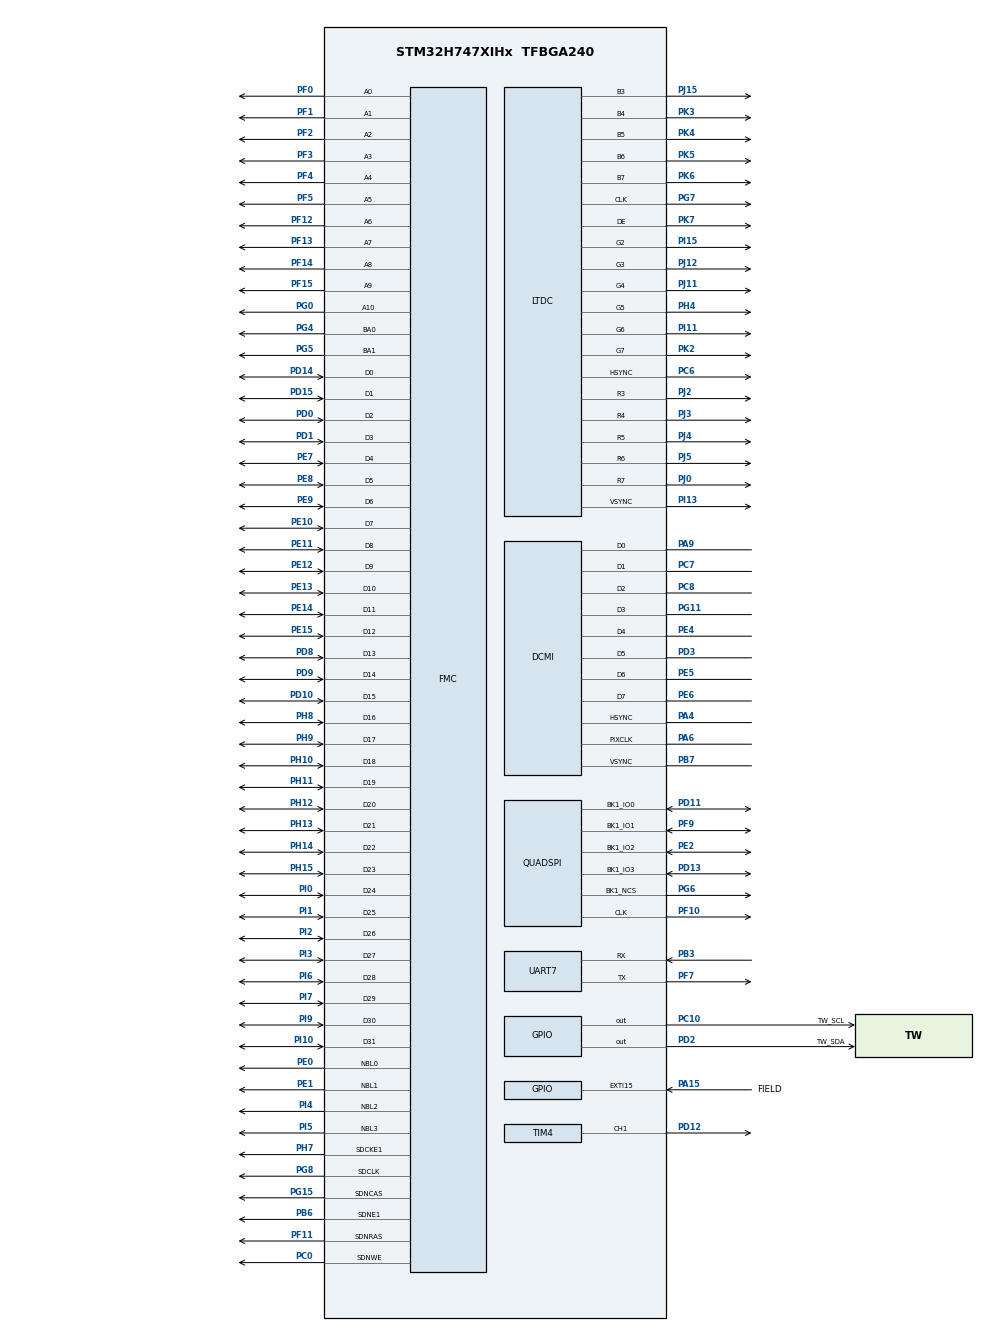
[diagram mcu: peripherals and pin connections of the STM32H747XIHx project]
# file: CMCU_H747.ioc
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CORTEX_M7.BaseAddress-Cortex_Memory_Protection_Unit_Region0_Settings=0x2402BA00
CORTEX_M7.CPU_DCache=Enabled
CORTEX_M7.CPU_ICache=Enabled
CORTEX_M7.Enable-Cortex_Memory_Protection_Unit_Region0_Settings=MPU_REGION_ENABLE
CORTEX_M7.MPU_Control=__NULL
CORTEX_M7.Size-Cortex_Memory_Protection_Unit_Region0_Settings=MPU_REGION_SIZE_256B
CortexM4.IPs=BDMA,CORTEX_M4\:I,DEBUG,DMA,FATFS_M4\:I,FREERTOS_M4\:I,GPIO,IWDG2\:I,MDMA,NVIC2\:I,OPENAMP_M4\:I,PDM2PCM_M4\:I,PWR,RCC,RESMGR_UTILITY,SYS_M4\:I,USB_DEVICE_M4\:I,USB_HOST_M4\:I,VREFBUF,WWDG2\:I
CortexM7.IPs=BDMA\:I,CORTEX_M7\:I,DEBUG\:I,DMA\:I,FATFS_M7\:I,FREERTOS_M7\:I,GPIO\:I,IWDG1\:I,MDMA\:I,NVIC1\:I,OPENAMP_M7\:I,PDM2PCM_M7\:I,PWR\:I,RCC\:I,RESMGR_UTILITY\:I,SYS\:I,USB_DEVICE_M7\:I,USB_HOST_M7\:I,VREFBUF\:I,WWDG1\:I,FMC\:I,QUADSPI\:I,DMA2D\:I,CRC\:I,TIM4\:I,UART7\:I,LTDC\:I,DSIHOST\:I,DCMI\:I,TIM6\:I
CortexM7.Pins=PC10,PA15 (JTDI),PD2
DCMI.JPEGMode=DCMI_JPEG_DISABLE
DCMI.PCKPolarity=DCMI_PCKPOLARITY_RISING
DMA2D.ColorMode=DMA2D_OUTPUT_RGB565
Dma.DCMI.0.Direction=DMA_PERIPH_TO_MEMORY
Dma.DCMI.0.EventEnable=DISABLE
Dma.DCMI.0.FIFOMode=DMA_FIFOMODE_ENABLE
Dma.DCMI.0.FIFOThreshold=DMA_FIFO_THRESHOLD_FULL
Dma.DCMI.0.Instance=DMA1_Stream2
Dma.DCMI.0.MemBurst=DMA_MBURST_INC4
Dma.DCMI.0.MemDataAlignment=DMA_MDATAALIGN_WORD
Dma.DCMI.0.MemInc=DMA_MINC_ENABLE
Dma.DCMI.0.Mode=DMA_CIRCULAR
Dma.DCMI.0.PeriphBurst=DMA_PBURST_SINGLE
Dma.DCMI.0.PeriphDataAlignment=DMA_PDATAALIGN_WORD
Dma.DCMI.0.PeriphInc=DMA_PINC_DISABLE
Dma.DCMI.0.Polarity=HAL_DMAMUX_REQ_GEN_RISING
Dma.DCMI.0.Priority=DMA_PRIORITY_VERY_HIGH
Dma.DCMI.0.RequestNumber=1
Dma.DCMI.0.SignalID=NONE
Dma.DCMI.0.SyncEnable=DISABLE
Dma.DCMI.0.SyncPolarity=HAL_DMAMUX_SYNC_NO_EVENT
Dma.DCMI.0.SyncRequestNumber=1
Dma.DCMI.0.SyncSignalID=NONE
Dma.Request0=DCMI
FMC.BankMapConfig=FMC_SWAPBMAP_SDRAM_SRAM
FMC.CASLatency1=FMC_SDRAM_CAS_LATENCY_3
FMC.ExitSelfRefreshDelay1=10
FMC.LoadToActiveDelay1=3
FMC.RCDDelay1=3
FMC.RPDelay1=3
FMC.ReadBurst1=FMC_SDRAM_RBURST_ENABLE
FMC.ReadPipeDelay1=FMC_SDRAM_RPIPE_DELAY_2
FMC.RowCycleDelay1=10
FMC.SDClockPeriod1=FMC_SDRAM_CLOCK_PERIOD_2
FMC.SelfRefreshTime1=6
FMC.WriteRecoveryTime1=6
LTDC.ActiveW=800
LTDC.Alpha_L0=255
LTDC.FBStartAdress_L0=0x70000000
LTDC.HBP=40
LTDC.HFP=40
LTDC.HSync=48
LTDC.ImageHeight_L0=480
LTDC.ImageWidth_L0=800
LTDC.Layers=0
LTDC.PixelFormat_L0=LTDC_PIXEL_FORMAT_RGB565
LTDC.VBP=29
LTDC.VFP=13
LTDC.VSync=3
LTDC.WindowX1_L0=800
LTDC.WindowY1_L0=480
Mcu.Family=STM32H7
Mcu.Name=STM32H747XIHx
Mcu.Package=TFBGA240
NVIC1.DCMI_IRQn=true\:5\:0\:true\:false\:true\:true\:true\:true
NVIC1.DMA1_Stream2_IRQn=true\:5\:0\:true\:false\:true\:false\:true\:true
NVIC1.DMA2D_IRQn=true\:0\:0\:false\:false\:true\:true\:true\:true
NVIC1.EXTI15_10_IRQn=true\:5\:0\:true\:false\:true\:true\:true\:true
NVIC1.FMC_IRQn=true\:0\:0\:false\:false\:true\:true\:true\:true
NVIC1.LTDC_ER_IRQn=true\:0\:0\:false\:false\:true\:true\:true\:true
NVIC1.LTDC_IRQn=true\:0\:0\:false\:false\:true\:true\:true\:true
NVIC1.PriorityGroup=NVIC_PRIORITYGROUP_4
NVIC1.UART7_IRQn=true\:0\:0\:false\:false\:true\:true\:true\:true
NVIC2.PriorityGroup=NVIC_PRIORITYGROUP_4
PA13\ (JTMS/SWDIO).Mode=Serial_Wire
PA13\ (JTMS/SWDIO).PinAttribute=CortexM7
PA13\ (JTMS/SWDIO).Signal=DEBUG_JTMS-SWDIO
PA14\ (JTCK/SWCLK).Mode=Serial_Wire
PA14\ (JTCK/SWCLK).PinAttribute=CortexM7
PA14\ (JTCK/SWCLK).Signal=DEBUG_JTCK-SWCLK
PA15\ (JTDI).GPIO_Label=FIELD
PA15\ (JTDI).GPIO_ModeDefaultEXTI=GPIO_MODE_IT_RISING_FALLING
PA15\ (JTDI).PinAttribute=CortexM7
PA15\ (JTDI).Signal=GPXTI15
PA4.Mode=Slave_8_bits_External_Synchro
PA4.PinAttribute=CortexM7
PA4.Signal=DCMI_HSYNC
PA6.Mode=Slave_8_bits_External_Synchro
PA6.PinAttribute=CortexM7
PA6.Signal=DCMI_PIXCLK
PA9.Mode=Slave_8_bits_External_Synchro
PA9.PinAttribute=CortexM7
PA9.Signal=DCMI_D0
PB3\ (JTDO/TRACESWO).Mode=Asynchronous
PB3\ (JTDO/TRACESWO).PinAttribute=CortexM7
PB3\ (JTDO/TRACESWO).Signal=UART7_RX
PB6.Mode=SdramChipSelect2_1
PB6.PinAttribute=CortexM7
PB6.Signal=FMC_SDNE1
PB7.Mode=Slave_8_bits_External_Synchro
PB7.PinAttribute=CortexM7
PB7.Signal=DCMI_VSYNC
PC0.PinAttribute=CortexM7
PC0.Signal=FMC_SDNWE
PC10.GPIO_Label=TW_SCL
PC10.GPIO_ModeDefaultOutputPP=GPIO_MODE_OUTPUT_PP
PC10.GPIO_PuPd=GPIO_NOPULL
PC10.GPIO_Speed=GPIO_SPEED_FREQ_LOW
PC10.PinAttribute=CortexM7
PC10.PinState=GPIO_PIN_SET
PC10.Signal=GPIO_Output
PC6.GPIO_Speed=GPIO_SPEED_FREQ_VERY_HIGH
PC6.Mode=RGB565
PC6.PinAttribute=CortexM7
PC6.Signal=LTDC_HSYNC
PC7.Mode=Slave_8_bits_External_Synchro
PC7.PinAttribute=CortexM7
PC7.Signal=DCMI_D1
PC8.Mode=Slave_8_bits_External_Synchro
PC8.PinAttribute=CortexM7
PC8.Signal=DCMI_D2
PD0.PinAttribute=CortexM7
PD0.Signal=FMC_D2_DA2
PD1.PinAttribute=CortexM7
PD1.Signal=FMC_D3_DA3
PD10.PinAttribute=CortexM7
PD10.Signal=FMC_D15_DA15
PD11.Mode=Single Bank 1
PD11.PinAttribute=CortexM7
PD11.Signal=QUADSPI_BK1_IO0
PD12.PinAttribute=CortexM7
PD12.Signal=S_TIM4_CH1
PD13.Mode=Single Bank 1
PD13.PinAttribute=CortexM7
PD13.Signal=QUADSPI_BK1_IO3
PD14.PinAttribute=CortexM7
PD14.Signal=FMC_D0_DA0
PD15.PinAttribute=CortexM7
PD15.Signal=FMC_D1_DA1
PD2.GPIO_Label=TW_SDA
PD2.GPIO_ModeDefaultOutputPP=GPIO_MODE_OUTPUT_OD
PD2.GPIO_PuPd=GPIO_PULLUP
PD2.GPIO_Speed=GPIO_SPEED_FREQ_LOW
PD2.PinAttribute=CortexM7
PD2.PinState=GPIO_PIN_SET
PD2.Signal=GPIO_Output
PD3.Mode=Slave_8_bits_External_Synchro
PD3.PinAttribute=CortexM7
PD3.Signal=DCMI_D5
PD8.PinAttribute=CortexM7
PD8.Signal=FMC_D13_DA13
PD9.PinAttribute=CortexM7
PD9.Signal=FMC_D14_DA14
PE0.PinAttribute=CortexM7
PE0.Signal=FMC_NBL0
PE1.PinAttribute=CortexM7
PE1.Signal=FMC_NBL1
PE10.PinAttribute=CortexM7
PE10.Signal=FMC_D7_DA7
PE11.PinAttribute=CortexM7
PE11.Signal=FMC_D8_DA8
PE12.PinAttribute=CortexM7
PE12.Signal=FMC_D9_DA9
PE13.PinAttribute=CortexM7
PE13.Signal=FMC_D10_DA10
PE14.PinAttribute=CortexM7
PE14.Signal=FMC_D11_DA11
PE15.PinAttribute=CortexM7
PE15.Signal=FMC_D12_DA12
PE2.Mode=Single Bank 1
PE2.PinAttribute=CortexM7
PE2.Signal=QUADSPI_BK1_IO2
PE4.Mode=Slave_8_bits_External_Synchro
PE4.PinAttribute=CortexM7
PE4.Signal=DCMI_D4
PE5.Mode=Slave_8_bits_External_Synchro
PE5.PinAttribute=CortexM7
PE5.Signal=DCMI_D6
PE6.Mode=Slave_8_bits_External_Synchro
PE6.PinAttribute=CortexM7
PE6.Signal=DCMI_D7
PE7.PinAttribute=CortexM7
PE7.Signal=FMC_D4_DA4
PE8.PinAttribute=CortexM7
PE8.Signal=FMC_D5_DA5
PE9.PinAttribute=CortexM7
PE9.Signal=FMC_D6_DA6
PF0.PinAttribute=CortexM7
PF0.Signal=FMC_A0
PF1.PinAttribute=CortexM7
PF1.Signal=FMC_A1
PF10.Mode=Single Bank 1
PF10.PinAttribute=CortexM7
PF10.Signal=QUADSPI_CLK
PF11.PinAttribute=CortexM7
PF11.Signal=FMC_SDNRAS
PF12.PinAttribute=CortexM7
PF12.Signal=FMC_A6
PF13.PinAttribute=CortexM7
PF13.Signal=FMC_A7
PF14.PinAttribute=CortexM7
PF14.Signal=FMC_A8
PF15.PinAttribute=CortexM7
PF15.Signal=FMC_A9
PF2.PinAttribute=CortexM7
PF2.Signal=FMC_A2
PF3.PinAttribute=CortexM7
PF3.Signal=FMC_A3
PF4.PinAttribute=CortexM7
PF4.Signal=FMC_A4
PF5.PinAttribute=CortexM7
PF5.Signal=FMC_A5
PF7.Mode=Asynchronous
PF7.PinAttribute=CortexM7
PF7.Signal=UART7_TX
PF9.Mode=Single Bank 1
PF9.PinAttribute=CortexM7
PF9.Signal=QUADSPI_BK1_IO1
PG0.PinAttribute=CortexM7
PG0.Signal=FMC_A10
PG11.Mode=Slave_8_bits_External_Synchro
PG11.PinAttribute=CortexM7
PG11.Signal=DCMI_D3
PG15.PinAttribute=CortexM7
PG15.Signal=FMC_SDNCAS
PG4.PinAttribute=CortexM7
PG4.Signal=FMC_A14_BA0
PG5.PinAttribute=CortexM7
PG5.Signal=FMC_A15_BA1
PG6.Mode=Single Bank 1
PG6.PinAttribute=CortexM7
PG6.Signal=QUADSPI_BK1_NCS
PG7.GPIO_Speed=GPIO_SPEED_FREQ_VERY_HIGH
PG7.Mode=RGB565
PG7.PinAttribute=CortexM7
PG7.Signal=LTDC_CLK
PG8.PinAttribute=CortexM7
PG8.Signal=FMC_SDCLK
PH0-OSC_IN\ (PH0).Mode=HSE-External-Oscillator
PH0-OSC_IN\ (PH0).PinAttribute=Free
PH0-OSC_IN\ (PH0).Signal=RCC_OSC_IN
PH1-OSC_OUT\ (PH1).Mode=HSE-External-Oscillator
PH1-OSC_OUT\ (PH1).PinAttribute=Free
PH1-OSC_OUT\ (PH1).Signal=RCC_OSC_OUT
PH10.PinAttribute=CortexM7
PH10.Signal=FMC_D18
PH11.PinAttribute=CortexM7
PH11.Signal=FMC_D19
PH12.PinAttribute=CortexM7
PH12.Signal=FMC_D20
PH13.PinAttribute=CortexM7
PH13.Signal=FMC_D21
PH14.PinAttribute=CortexM7
PH14.Signal=FMC_D22
PH15.PinAttribute=CortexM7
PH15.Signal=FMC_D23
PH4.GPIO_Mode=GPIO_MODE_AF_PP
PH4.GPIO_PuPd=GPIO_NOPULL
PH4.GPIO_Speed=GPIO_SPEED_FREQ_VERY_HIGH
PH4.Mode=RGB565
PH4.PinAttribute=CortexM7
PH4.Signal=LTDC_G5
PH7.Mode=SdramChipSelect2_1
PH7.PinAttribute=CortexM7
PH7.Signal=FMC_SDCKE1
PH8.PinAttribute=CortexM7
PH8.Signal=FMC_D16
PH9.PinAttribute=CortexM7
PH9.Signal=FMC_D17
PI0.PinAttribute=CortexM7
PI0.Signal=FMC_D24
PI1.PinAttribute=CortexM7
PI1.Signal=FMC_D25
PI10.PinAttribute=CortexM7
PI10.Signal=FMC_D31
PI11.GPIO_Speed=GPIO_SPEED_FREQ_VERY_HIGH
PI11.Mode=RGB565
PI11.PinAttribute=CortexM7
PI11.Signal=LTDC_G6
PI13.GPIO_Speed=GPIO_SPEED_FREQ_VERY_HIGH
PI13.Mode=RGB565
PI13.PinAttribute=CortexM7
PI13.Signal=LTDC_VSYNC
PI15.GPIO_Mode=GPIO_MODE_AF_PP
PI15.GPIO_PuPd=GPIO_NOPULL
PI15.GPIO_Speed=GPIO_SPEED_FREQ_VERY_HIGH
PI15.Mode=RGB565
PI15.PinAttribute=CortexM7
PI15.Signal=LTDC_G2
PI2.PinAttribute=CortexM7
PI2.Signal=FMC_D26
PI3.PinAttribute=CortexM7
PI3.Signal=FMC_D27
PI4.PinAttribute=CortexM7
PI4.Signal=FMC_NBL2
PI5.PinAttribute=CortexM7
PI5.Signal=FMC_NBL3
PI6.PinAttribute=CortexM7
PI6.Signal=FMC_D28
PI7.PinAttribute=CortexM7
PI7.Signal=FMC_D29
PI9.PinAttribute=CortexM7
PI9.Signal=FMC_D30
PJ0.GPIO_Mode=GPIO_MODE_AF_PP
PJ0.GPIO_PuPd=GPIO_NOPULL
PJ0.GPIO_Speed=GPIO_SPEED_FREQ_VERY_HIGH
PJ0.Mode=RGB565
PJ0.PinAttribute=CortexM7
PJ0.Signal=LTDC_R7
PJ11.GPIO_Speed=GPIO_SPEED_FREQ_VERY_HIGH
PJ11.Mode=RGB565
PJ11.PinAttribute=CortexM7
PJ11.Signal=LTDC_G4
PJ12.GPIO_Mode=GPIO_MODE_AF_PP
PJ12.GPIO_PuPd=GPIO_NOPULL
PJ12.GPIO_Speed=GPIO_SPEED_FREQ_VERY_HIGH
PJ12.Mode=RGB565
PJ12.PinAttribute=CortexM7
PJ12.Signal=LTDC_G3
PJ15.GPIO_Speed=GPIO_SPEED_FREQ_VERY_HIGH
PJ15.Mode=RGB565
PJ15.PinAttribute=CortexM7
PJ15.Signal=LTDC_B3
PJ2.GPIO_Speed=GPIO_SPEED_FREQ_VERY_HIGH
PJ2.Mode=RGB565
PJ2.PinAttribute=CortexM7
PJ2.Signal=LTDC_R3
PJ3.GPIO_Mode=GPIO_MODE_AF_PP
PJ3.GPIO_PuPd=GPIO_NOPULL
PJ3.GPIO_Speed=GPIO_SPEED_FREQ_VERY_HIGH
PJ3.Mode=RGB565
PJ3.PinAttribute=CortexM7
PJ3.Signal=LTDC_R4
PJ4.GPIO_Mode=GPIO_MODE_AF_PP
PJ4.GPIO_PuPd=GPIO_NOPULL
PJ4.GPIO_Speed=GPIO_SPEED_FREQ_VERY_HIGH
PJ4.Mode=RGB565
PJ4.PinAttribute=CortexM7
PJ4.Signal=LTDC_R5
PJ5.GPIO_Mode=GPIO_MODE_AF_PP
PJ5.GPIO_PuPd=GPIO_NOPULL
PJ5.GPIO_Speed=GPIO_SPEED_FREQ_VERY_HIGH
PJ5.Mode=RGB565
PJ5.PinAttribute=CortexM7
PJ5.Signal=LTDC_R6
PK2.GPIO_Speed=GPIO_SPEED_FREQ_VERY_HIGH
PK2.Mode=RGB565
PK2.PinAttribute=CortexM7
PK2.Signal=LTDC_G7
PK3.GPIO_Speed=GPIO_SPEED_FREQ_VERY_HIGH
PK3.Mode=RGB565
PK3.PinAttribute=CortexM7
PK3.Signal=LTDC_B4
PK4.GPIO_Speed=GPIO_SPEED_FREQ_VERY_HIGH
PK4.Mode=RGB565
PK4.PinAttribute=CortexM7
PK4.Signal=LTDC_B5
PK5.GPIO_Speed=GPIO_SPEED_FREQ_VERY_HIGH
PK5.Mode=RGB565
PK5.PinAttribute=CortexM7
PK5.Signal=LTDC_B6
PK6.GPIO_Speed=GPIO_SPEED_FREQ_VERY_HIGH
PK6.Mode=RGB565
PK6.PinAttribute=CortexM7
PK6.Signal=LTDC_B7
PK7.GPIO_Speed=GPIO_SPEED_FREQ_VERY_HIGH
PK7.Mode=RGB565
PK7.PinAttribute=CortexM7
PK7.Signal=LTDC_DE
ProjectManager.HeapSize=M4-0x200,M7-0x200
ProjectManager.StackSize=M4-0x400,M7-0x400
ProjectManager.TargetToolchain=STM32CubeIDE
QUADSPI.ChipSelectHighTime=QSPI_CS_HIGH_TIME_3_CYCLE
QUADSPI.ClockPrescaler=2
QUADSPI.FifoThreshold=4
QUADSPI.FlashSize=25
RCC.ADCFreq_Value=280000000
RCC.APB1Freq_Value=120000000
RCC.APB2Freq_Value=120000000
RCC.APB3Freq_Value=120000000
RCC.APB4Freq_Value=120000000
RCC.CortexFreq_Value=480000000
RCC.D1PPRE=RCC_APB3_DIV2
RCC.D2PPRE1=RCC_APB1_DIV2
RCC.D2PPRE2=RCC_APB2_DIV2
RCC.D3PPRE=RCC_APB4_DIV2
RCC.DIVM1=5
RCC.DIVM2=5
RCC.DIVM3=25
RCC.DIVN1=192
RCC.DIVN2=112
RCC.DIVN3=240
RCC.DIVQ1=8
RCC.DIVQ2=7
RCC.DIVQ3=4
RCC.DIVR1=4
RCC.DIVR3=8
RCC.FMCCLockSelection=RCC_FMCCLKSOURCE_PLL2
RCC.HCLKFreq_Value=240000000
RCC.HPRE=RCC_HCLK_DIV2
RCC.PLL1_VCI_Range-AdvancedSettings=RCC_PLL1VCIRANGE_0
RCC.PLL2FRACN=0
RCC.PLL3FRACN=0
RCC.PLLFRACN=0
RCC.PLLSourceVirtual=RCC_PLLSOURCE_HSE
RCC.QSPICLockSelection=RCC_QSPICLKSOURCE_PLL
RCC.SYSCLKFreq_VALUE=480000000
RCC.SYSCLKSource=RCC_SYSCLKSOURCE_PLLCLK
RCC.USBFreq_Value=120000000
SH.FMC_A0.0=FMC_A0,11b-sda1
SH.FMC_A1.0=FMC_A1,11b-sda1
SH.FMC_A10.0=FMC_A10,11b-sda1
SH.FMC_A14_BA0.0=FMC_BA0,FourSdramBanks1
SH.FMC_A15_BA1.0=FMC_BA1,FourSdramBanks1
SH.FMC_A2.0=FMC_A2,11b-sda1
SH.FMC_A3.0=FMC_A3,11b-sda1
SH.FMC_A4.0=FMC_A4,11b-sda1
SH.FMC_A5.0=FMC_A5,11b-sda1
SH.FMC_A6.0=FMC_A6,11b-sda1
SH.FMC_A7.0=FMC_A7,11b-sda1
SH.FMC_A8.0=FMC_A8,11b-sda1
SH.FMC_A9.0=FMC_A9,11b-sda1
SH.FMC_D0_DA0.0=FMC_D0,sd-32b-d1
SH.FMC_D10_DA10.0=FMC_D10,sd-32b-d1
SH.FMC_D11_DA11.0=FMC_D11,sd-32b-d1
SH.FMC_D12_DA12.0=FMC_D12,sd-32b-d1
SH.FMC_D13_DA13.0=FMC_D13,sd-32b-d1
SH.FMC_D14_DA14.0=FMC_D14,sd-32b-d1
SH.FMC_D15_DA15.0=FMC_D15,sd-32b-d1
SH.FMC_D16.0=FMC_D16,sd-32b-d1
SH.FMC_D17.0=FMC_D17,sd-32b-d1
SH.FMC_D18.0=FMC_D18,sd-32b-d1
SH.FMC_D19.0=FMC_D19,sd-32b-d1
SH.FMC_D1_DA1.0=FMC_D1,sd-32b-d1
SH.FMC_D20.0=FMC_D20,sd-32b-d1
SH.FMC_D21.0=FMC_D21,sd-32b-d1
SH.FMC_D22.0=FMC_D22,sd-32b-d1
SH.FMC_D23.0=FMC_D23,sd-32b-d1
SH.FMC_D24.0=FMC_D24,sd-32b-d1
SH.FMC_D25.0=FMC_D25,sd-32b-d1
SH.FMC_D26.0=FMC_D26,sd-32b-d1
SH.FMC_D27.0=FMC_D27,sd-32b-d1
SH.FMC_D28.0=FMC_D28,sd-32b-d1
SH.FMC_D29.0=FMC_D29,sd-32b-d1
SH.FMC_D2_DA2.0=FMC_D2,sd-32b-d1
SH.FMC_D30.0=FMC_D30,sd-32b-d1
SH.FMC_D31.0=FMC_D31,sd-32b-d1
SH.FMC_D3_DA3.0=FMC_D3,sd-32b-d1
SH.FMC_D4_DA4.0=FMC_D4,sd-32b-d1
SH.FMC_D5_DA5.0=FMC_D5,sd-32b-d1
SH.FMC_D6_DA6.0=FMC_D6,sd-32b-d1
SH.FMC_D7_DA7.0=FMC_D7,sd-32b-d1
SH.FMC_D8_DA8.0=FMC_D8,sd-32b-d1
SH.FMC_D9_DA9.0=FMC_D9,sd-32b-d1
SH.FMC_NBL0.0=FMC_NBL0,Sd4ByteEnable1
SH.FMC_NBL1.0=FMC_NBL1,Sd4ByteEnable1
SH.FMC_NBL2.0=FMC_NBL2,Sd4ByteEnable1
SH.FMC_NBL3.0=FMC_NBL3,Sd4ByteEnable1
SH.FMC_SDCLK.0=FMC_SDCLK,11b-sda1
SH.FMC_SDNCAS.0=FMC_SDNCAS,11b-sda1
SH.FMC_SDNRAS.0=FMC_SDNRAS,11b-sda1
SH.FMC_SDNWE.0=FMC_SDNWE,11b-sda1
SH.S_TIM4_CH1.0=TIM4_CH1,PWM Generation1 CH1
TIM4.Channel-PWM\ Generation1\ CH1=TIM_CHANNEL_1
TIM4.Period=99
TIM4.Prescaler=479
TIM4.Pulse-PWM\ Generation1\ CH1=49
TIM6.Prescaler=239
UART7.SwapParam=UART_ADVFEATURE_SWAP_ENABLE
VP_CRC_VS_CRC.Mode=CRC_Activate
VP_DMA2D_VS_DMA2D.Mode=DMA2D_Activate
VP_TIM4_VS_ClockSourceINT.Mode=Internal
VP_TIM6_VS_ClockSourceINT.Mode=Enable_Timer
board=custom

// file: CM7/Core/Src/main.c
/* USER CODE BEGIN Header */
/**
  ******************************************************************************
  * @file           : main.c
  * @brief          : Main program body
  ******************************************************************************
  * @attention
  *
  * Copyright (c) 2023 STMicroelectronics.
  * All rights reserved.
  *
  * This software is licensed under terms that can be found in the LICENSE file
  * in the root directory of this software component.
  * If no LICENSE file comes with this software, it is provided AS-IS.
  *
  ******************************************************************************
  */
/* USER CODE END Header */
#include "main.h"

/* USER CODE BEGIN Includes */
#include <stdio.h>

void CM7();
static void SDRAM_Initialization_Sequence(SDRAM_HandleTypeDef *hsdram, FMC_SDRAM_CommandTypeDef *Command);
FMC_SDRAM_CommandTypeDef command;
/* USER CODE END Includes */

/* USER CODE BEGIN PD */

#ifndef HSEM_ID_0
#define HSEM_ID_0 (0U) /* HW semaphore 0*/
#endif

/* USER CODE END PD */

CRC_HandleTypeDef hcrc;

DCMI_HandleTypeDef hdcmi;
DMA_HandleTypeDef hdma_dcmi;

DMA2D_HandleTypeDef hdma2d;

LTDC_HandleTypeDef hltdc;

QSPI_HandleTypeDef hqspi;

TIM_HandleTypeDef htim4;
TIM_HandleTypeDef htim6;

UART_HandleTypeDef huart7;

SDRAM_HandleTypeDef hsdram1;

void SystemClock_Config(void);
static void MX_GPIO_Init(void);
static void MX_DMA_Init(void);
static void MX_QUADSPI_Init(void);
static void MX_DMA2D_Init(void);
static void MX_CRC_Init(void);
static void MX_LTDC_Init(void);
static void MX_TIM4_Init(void);
static void MX_UART7_Init(void);
static void MX_FMC_Init(void);
static void MX_DCMI_Init(void);
static void MX_TIM6_Init(void);

int main(void)
{
/* USER CODE BEGIN Boot_Mode_Sequence_0 */
  int32_t timeout;
/* USER CODE END Boot_Mode_Sequence_0 */

  /* Enable I-Cache---------------------------------------------------------*/
  SCB_EnableICache();

  /* Enable D-Cache---------------------------------------------------------*/
  SCB_EnableDCache();

/* USER CODE BEGIN Boot_Mode_Sequence_1 */
  /* Wait until CPU2 boots and enters in stop mode or timeout*/

/* USER CODE END Boot_Mode_Sequence_1 */
  /* MCU Configuration--------------------------------------------------------*/

  /* Reset of all peripherals, Initializes the Flash interface and the Systick. */
  HAL_Init();

  /* USER CODE BEGIN Init */
#define PWR_LDO_SUPPLY PWR_CR3_SMPSEN
  /* USER CODE END Init */

  /* Configure the system clock */
  SystemClock_Config();
/* USER CODE BEGIN Boot_Mode_Sequence_2 */
/* When system initialization is finished, Cortex-M7 will release Cortex-M4 by means of
HSEM notification */
/*HW semaphore Clock enable*/
__HAL_RCC_HSEM_CLK_ENABLE();
/*Take HSEM */
HAL_HSEM_FastTake(HSEM_ID_0);
/*Release HSEM in order to notify the CPU2(CM4)*/
HAL_HSEM_Release(HSEM_ID_0,0);
/* wait until CPU2 wakes up from stop mode */
timeout = 0xFFFF;
while((__HAL_RCC_GET_FLAG(RCC_FLAG_D2CKRDY) == RESET) && (timeout-- > 0));
if ( timeout < 0 )
{
Error_Handler();
}
/* USER CODE END Boot_Mode_Sequence_2 */

  /* Initialize all configured peripherals */
  MX_GPIO_Init();
  MX_DMA_Init();
  MX_QUADSPI_Init();
  MX_DMA2D_Init();
  MX_CRC_Init();
  MX_LTDC_Init();
  MX_TIM4_Init();
  MX_UART7_Init();
  MX_FMC_Init();
  MX_DCMI_Init();
  MX_TIM6_Init();
  /* USER CODE BEGIN 2 */
SDRAM_Initialization_Sequence(&hsdram1, &command);
CM7();
  /* USER CODE END 2 */

  /* Infinite loop */
  while (1)
  {

  }
}

void SystemClock_Config(void)
{
  RCC_OscInitTypeDef RCC_OscInitStruct = {0};
  RCC_ClkInitTypeDef RCC_ClkInitStruct = {0};

  /** Supply configuration update enable
  */
  HAL_PWREx_ConfigSupply(PWR_LDO_SUPPLY);

  /** Configure the main internal regulator output voltage
  */
  __HAL_PWR_VOLTAGESCALING_CONFIG(PWR_REGULATOR_VOLTAGE_SCALE1);

  while(!__HAL_PWR_GET_FLAG(PWR_FLAG_VOSRDY)) {}

  __HAL_RCC_SYSCFG_CLK_ENABLE();
  __HAL_PWR_VOLTAGESCALING_CONFIG(PWR_REGULATOR_VOLTAGE_SCALE0);

  while(!__HAL_PWR_GET_FLAG(PWR_FLAG_VOSRDY)) {}

  /** Initializes the RCC Oscillators according to the specified parameters
  * in the RCC_OscInitTypeDef structure.
  */
  RCC_OscInitStruct.OscillatorType = RCC_OSCILLATORTYPE_HSE;
  RCC_OscInitStruct.HSEState = RCC_HSE_ON;
  RCC_OscInitStruct.PLL.PLLState = RCC_PLL_ON;
  RCC_OscInitStruct.PLL.PLLSource = RCC_PLLSOURCE_HSE;
  RCC_OscInitStruct.PLL.PLLM = 5;
  RCC_OscInitStruct.PLL.PLLN = 192;
  RCC_OscInitStruct.PLL.PLLP = 2;
  RCC_OscInitStruct.PLL.PLLQ = 8;
  RCC_OscInitStruct.PLL.PLLR = 4;
  RCC_OscInitStruct.PLL.PLLRGE = RCC_PLL1VCIRANGE_2;
  RCC_OscInitStruct.PLL.PLLVCOSEL = RCC_PLL1VCOWIDE;
  RCC_OscInitStruct.PLL.PLLFRACN = 0;
  if (HAL_RCC_OscConfig(&RCC_OscInitStruct) != HAL_OK)
  {
    Error_Handler();
  }

  /** Initializes the CPU, AHB and APB buses clocks
  */
  RCC_ClkInitStruct.ClockType = RCC_CLOCKTYPE_HCLK|RCC_CLOCKTYPE_SYSCLK
                              |RCC_CLOCKTYPE_PCLK1|RCC_CLOCKTYPE_PCLK2
                              |RCC_CLOCKTYPE_D3PCLK1|RCC_CLOCKTYPE_D1PCLK1;
  RCC_ClkInitStruct.SYSCLKSource = RCC_SYSCLKSOURCE_PLLCLK;
  RCC_ClkInitStruct.SYSCLKDivider = RCC_SYSCLK_DIV1;
  RCC_ClkInitStruct.AHBCLKDivider = RCC_HCLK_DIV2;
  RCC_ClkInitStruct.APB3CLKDivider = RCC_APB3_DIV2;
  RCC_ClkInitStruct.APB1CLKDivider = RCC_APB1_DIV2;
  RCC_ClkInitStruct.APB2CLKDivider = RCC_APB2_DIV2;
  RCC_ClkInitStruct.APB4CLKDivider = RCC_APB4_DIV2;

  if (HAL_RCC_ClockConfig(&RCC_ClkInitStruct, FLASH_LATENCY_4) != HAL_OK)
  {
    Error_Handler();
  }
}

static void MX_CRC_Init(void)
{

  hcrc.Instance = CRC;
  hcrc.Init.DefaultPolynomialUse = DEFAULT_POLYNOMIAL_ENABLE;
  hcrc.Init.DefaultInitValueUse = DEFAULT_INIT_VALUE_ENABLE;
  hcrc.Init.InputDataInversionMode = CRC_INPUTDATA_INVERSION_NONE;
  hcrc.Init.OutputDataInversionMode = CRC_OUTPUTDATA_INVERSION_DISABLE;
  hcrc.InputDataFormat = CRC_INPUTDATA_FORMAT_BYTES;
  if (HAL_CRC_Init(&hcrc) != HAL_OK)
  {
    Error_Handler();
  }

}

static void MX_DCMI_Init(void)
{

  hdcmi.Instance = DCMI;
  hdcmi.Init.SynchroMode = DCMI_SYNCHRO_HARDWARE;
  hdcmi.Init.PCKPolarity = DCMI_PCKPOLARITY_RISING;
  hdcmi.Init.VSPolarity = DCMI_VSPOLARITY_LOW;
  hdcmi.Init.HSPolarity = DCMI_HSPOLARITY_LOW;
  hdcmi.Init.CaptureRate = DCMI_CR_ALL_FRAME;
  hdcmi.Init.ExtendedDataMode = DCMI_EXTEND_DATA_8B;
  hdcmi.Init.JPEGMode = DCMI_JPEG_DISABLE;
  hdcmi.Init.ByteSelectMode = DCMI_BSM_ALL;
  hdcmi.Init.ByteSelectStart = DCMI_OEBS_ODD;
  hdcmi.Init.LineSelectMode = DCMI_LSM_ALL;
  hdcmi.Init.LineSelectStart = DCMI_OELS_ODD;
  if (HAL_DCMI_Init(&hdcmi) != HAL_OK)
  {
    Error_Handler();
  }

}

static void MX_DMA2D_Init(void)
{

  hdma2d.Instance = DMA2D;
  hdma2d.Init.Mode = DMA2D_M2M;
  hdma2d.Init.ColorMode = DMA2D_OUTPUT_RGB565;
  hdma2d.Init.OutputOffset = 0;
  hdma2d.LayerCfg[1].InputOffset = 0;
  hdma2d.LayerCfg[1].InputColorMode = DMA2D_INPUT_RGB565;
  hdma2d.LayerCfg[1].AlphaMode = DMA2D_NO_MODIF_ALPHA;
  hdma2d.LayerCfg[1].InputAlpha = 0;
  hdma2d.LayerCfg[1].AlphaInverted = DMA2D_REGULAR_ALPHA;
  hdma2d.LayerCfg[1].RedBlueSwap = DMA2D_RB_REGULAR;
  hdma2d.LayerCfg[1].ChromaSubSampling = DMA2D_NO_CSS;
  if (HAL_DMA2D_Init(&hdma2d) != HAL_OK)
  {
    Error_Handler();
  }
  if (HAL_DMA2D_ConfigLayer(&hdma2d, 1) != HAL_OK)
  {
    Error_Handler();
  }

}

static void MX_LTDC_Init(void)
{

  LTDC_LayerCfgTypeDef pLayerCfg = {0};

  hltdc.Instance = LTDC;
  hltdc.Init.HSPolarity = LTDC_HSPOLARITY_AL;
  hltdc.Init.VSPolarity = LTDC_VSPOLARITY_AL;
  hltdc.Init.DEPolarity = LTDC_DEPOLARITY_AL;
  hltdc.Init.PCPolarity = LTDC_PCPOLARITY_IPC;
  hltdc.Init.HorizontalSync = 47;
  hltdc.Init.VerticalSync = 2;
  hltdc.Init.AccumulatedHBP = 87;
  hltdc.Init.AccumulatedVBP = 31;
  hltdc.Init.AccumulatedActiveW = 887;
  hltdc.Init.AccumulatedActiveH = 511;
  hltdc.Init.TotalWidth = 927;
  hltdc.Init.TotalHeigh = 524;
  hltdc.Init.Backcolor.Blue = 0;
  hltdc.Init.Backcolor.Green = 0;
  hltdc.Init.Backcolor.Red = 0;
  if (HAL_LTDC_Init(&hltdc) != HAL_OK)
  {
    Error_Handler();
  }
  pLayerCfg.WindowX0 = 0;
  pLayerCfg.WindowX1 = 800;
  pLayerCfg.WindowY0 = 0;
  pLayerCfg.WindowY1 = 480;
  pLayerCfg.PixelFormat = LTDC_PIXEL_FORMAT_RGB565;
  pLayerCfg.Alpha = 255;
  pLayerCfg.Alpha0 = 0;
  pLayerCfg.BlendingFactor1 = LTDC_BLENDING_FACTOR1_CA;
  pLayerCfg.BlendingFactor2 = LTDC_BLENDING_FACTOR2_CA;
  pLayerCfg.FBStartAdress = 0x70000000;
  pLayerCfg.ImageWidth = 800;
  pLayerCfg.ImageHeight = 480;
  pLayerCfg.Backcolor.Blue = 0;
  pLayerCfg.Backcolor.Green = 0;
  pLayerCfg.Backcolor.Red = 0;
  if (HAL_LTDC_ConfigLayer(&hltdc, &pLayerCfg, 0) != HAL_OK)
  {
    Error_Handler();
  }

}

static void MX_QUADSPI_Init(void)
{

  /* QUADSPI parameter configuration*/
  hqspi.Instance = QUADSPI;
  hqspi.Init.ClockPrescaler = 2;
  hqspi.Init.FifoThreshold = 4;
  hqspi.Init.SampleShifting = QSPI_SAMPLE_SHIFTING_NONE;
  hqspi.Init.FlashSize = 25;
  hqspi.Init.ChipSelectHighTime = QSPI_CS_HIGH_TIME_3_CYCLE;
  hqspi.Init.ClockMode = QSPI_CLOCK_MODE_0;
  hqspi.Init.FlashID = QSPI_FLASH_ID_1;
  hqspi.Init.DualFlash = QSPI_DUALFLASH_DISABLE;
  if (HAL_QSPI_Init(&hqspi) != HAL_OK)
  {
    Error_Handler();
  }

}

static void MX_TIM4_Init(void)
{

  TIM_ClockConfigTypeDef sClockSourceConfig = {0};
  TIM_MasterConfigTypeDef sMasterConfig = {0};
  TIM_OC_InitTypeDef sConfigOC = {0};

  htim4.Instance = TIM4;
  htim4.Init.Prescaler = 479;
  htim4.Init.CounterMode = TIM_COUNTERMODE_UP;
  htim4.Init.Period = 99;
  htim4.Init.ClockDivision = TIM_CLOCKDIVISION_DIV1;
  htim4.Init.AutoReloadPreload = TIM_AUTORELOAD_PRELOAD_DISABLE;
  if (HAL_TIM_Base_Init(&htim4) != HAL_OK)
  {
    Error_Handler();
  }
  sClockSourceConfig.ClockSource = TIM_CLOCKSOURCE_INTERNAL;
  if (HAL_TIM_ConfigClockSource(&htim4, &sClockSourceConfig) != HAL_OK)
  {
    Error_Handler();
  }
  if (HAL_TIM_PWM_Init(&htim4) != HAL_OK)
  {
    Error_Handler();
  }
  sMasterConfig.MasterOutputTrigger = TIM_TRGO_RESET;
  sMasterConfig.MasterSlaveMode = TIM_MASTERSLAVEMODE_DISABLE;
  if (HAL_TIMEx_MasterConfigSynchronization(&htim4, &sMasterConfig) != HAL_OK)
  {
    Error_Handler();
  }
  sConfigOC.OCMode = TIM_OCMODE_PWM1;
  sConfigOC.Pulse = 49;
  sConfigOC.OCPolarity = TIM_OCPOLARITY_HIGH;
  sConfigOC.OCFastMode = TIM_OCFAST_DISABLE;
  if (HAL_TIM_PWM_ConfigChannel(&htim4, &sConfigOC, TIM_CHANNEL_1) != HAL_OK)
  {
    Error_Handler();
  }
  HAL_TIM_MspPostInit(&htim4);

}

static void MX_TIM6_Init(void)
{

  TIM_MasterConfigTypeDef sMasterConfig = {0};

  htim6.Instance = TIM6;
  htim6.Init.Prescaler = 239;
  htim6.Init.CounterMode = TIM_COUNTERMODE_UP;
  htim6.Init.Period = 65535;
  htim6.Init.AutoReloadPreload = TIM_AUTORELOAD_PRELOAD_DISABLE;
  if (HAL_TIM_Base_Init(&htim6) != HAL_OK)
  {
    Error_Handler();
  }
  sMasterConfig.MasterOutputTrigger = TIM_TRGO_RESET;
  sMasterConfig.MasterSlaveMode = TIM_MASTERSLAVEMODE_DISABLE;
  if (HAL_TIMEx_MasterConfigSynchronization(&htim6, &sMasterConfig) != HAL_OK)
  {
    Error_Handler();
  }

}

static void MX_UART7_Init(void)
{

  huart7.Instance = UART7;
  huart7.Init.BaudRate = 115200;
  huart7.Init.WordLength = UART_WORDLENGTH_8B;
  huart7.Init.StopBits = UART_STOPBITS_1;
  huart7.Init.Parity = UART_PARITY_NONE;
  huart7.Init.Mode = UART_MODE_TX_RX;
  huart7.Init.HwFlowCtl = UART_HWCONTROL_NONE;
  huart7.Init.OverSampling = UART_OVERSAMPLING_16;
  huart7.Init.OneBitSampling = UART_ONE_BIT_SAMPLE_DISABLE;
  huart7.Init.ClockPrescaler = UART_PRESCALER_DIV1;
  huart7.AdvancedInit.AdvFeatureInit = UART_ADVFEATURE_SWAP_INIT;
  huart7.AdvancedInit.Swap = UART_ADVFEATURE_SWAP_ENABLE;
  if (HAL_UART_Init(&huart7) != HAL_OK)
  {
    Error_Handler();
  }
  if (HAL_UARTEx_SetTxFifoThreshold(&huart7, UART_TXFIFO_THRESHOLD_1_8) != HAL_OK)
  {
    Error_Handler();
  }
  if (HAL_UARTEx_SetRxFifoThreshold(&huart7, UART_RXFIFO_THRESHOLD_1_8) != HAL_OK)
  {
    Error_Handler();
  }
  if (HAL_UARTEx_DisableFifoMode(&huart7) != HAL_OK)
  {
    Error_Handler();
  }

}

static void MX_DMA_Init(void)
{

  /* DMA controller clock enable */
  __HAL_RCC_DMA1_CLK_ENABLE();

  /* DMA interrupt init */
  /* DMA1_Stream2_IRQn interrupt configuration */
  HAL_NVIC_SetPriority(DMA1_Stream2_IRQn, 5, 0);
  HAL_NVIC_EnableIRQ(DMA1_Stream2_IRQn);

}

/* FMC initialization function */
void MX_FMC_Init(void)
{

  FMC_SDRAM_TimingTypeDef SdramTiming = {0};

  /** Perform the SDRAM1 memory initialization sequence
  */
  hsdram1.Instance = FMC_SDRAM_DEVICE;
  /* hsdram1.Init */
  hsdram1.Init.SDBank = FMC_SDRAM_BANK2;
  hsdram1.Init.ColumnBitsNumber = FMC_SDRAM_COLUMN_BITS_NUM_8;
  hsdram1.Init.RowBitsNumber = FMC_SDRAM_ROW_BITS_NUM_11;
  hsdram1.Init.MemoryDataWidth = FMC_SDRAM_MEM_BUS_WIDTH_32;
  hsdram1.Init.InternalBankNumber = FMC_SDRAM_INTERN_BANKS_NUM_4;
  hsdram1.Init.CASLatency = FMC_SDRAM_CAS_LATENCY_3;
  hsdram1.Init.WriteProtection = FMC_SDRAM_WRITE_PROTECTION_DISABLE;
  hsdram1.Init.SDClockPeriod = FMC_SDRAM_CLOCK_PERIOD_2;
  hsdram1.Init.ReadBurst = FMC_SDRAM_RBURST_ENABLE;
  hsdram1.Init.ReadPipeDelay = FMC_SDRAM_RPIPE_DELAY_2;
  /* SdramTiming */
  SdramTiming.LoadToActiveDelay = 3;
  SdramTiming.ExitSelfRefreshDelay = 10;
  SdramTiming.SelfRefreshTime = 6;
  SdramTiming.RowCycleDelay = 10;
  SdramTiming.WriteRecoveryTime = 6;
  SdramTiming.RPDelay = 3;
  SdramTiming.RCDDelay = 3;

  if (HAL_SDRAM_Init(&hsdram1, &SdramTiming) != HAL_OK)
  {
    Error_Handler( );
  }

  HAL_SetFMCMemorySwappingConfig(FMC_SWAPBMAP_SDRAM_SRAM);

}

static void MX_GPIO_Init(void)
{
  GPIO_InitTypeDef GPIO_InitStruct = {0};

  /* GPIO Ports Clock Enable */
  __HAL_RCC_GPIOI_CLK_ENABLE();
  __HAL_RCC_GPIOK_CLK_ENABLE();
  __HAL_RCC_GPIOC_CLK_ENABLE();
  __HAL_RCC_GPIOA_CLK_ENABLE();
  __HAL_RCC_GPIOE_CLK_ENABLE();
  __HAL_RCC_GPIOB_CLK_ENABLE();
  __HAL_RCC_GPIOG_CLK_ENABLE();
  __HAL_RCC_GPIOJ_CLK_ENABLE();
  __HAL_RCC_GPIOD_CLK_ENABLE();
  __HAL_RCC_GPIOH_CLK_ENABLE();
  __HAL_RCC_GPIOF_CLK_ENABLE();

  /*Configure GPIO pin Output Level */
  HAL_GPIO_WritePin(TW_SCL_GPIO_Port, TW_SCL_Pin, GPIO_PIN_SET);

  /*Configure GPIO pin Output Level */
  HAL_GPIO_WritePin(TW_SDA_GPIO_Port, TW_SDA_Pin, GPIO_PIN_SET);

  /*Configure GPIO pin : TW_SCL_Pin */
  GPIO_InitStruct.Pin = TW_SCL_Pin;
  GPIO_InitStruct.Mode = GPIO_MODE_OUTPUT_PP;
  GPIO_InitStruct.Pull = GPIO_NOPULL;
  GPIO_InitStruct.Speed = GPIO_SPEED_FREQ_LOW;
  HAL_GPIO_Init(TW_SCL_GPIO_Port, &GPIO_InitStruct);

  /*Configure GPIO pin : FIELD_Pin */
  GPIO_InitStruct.Pin = FIELD_Pin;
  GPIO_InitStruct.Mode = GPIO_MODE_IT_RISING_FALLING;
  GPIO_InitStruct.Pull = GPIO_NOPULL;
  HAL_GPIO_Init(FIELD_GPIO_Port, &GPIO_InitStruct);

  /*Configure GPIO pin : TW_SDA_Pin */
  GPIO_InitStruct.Pin = TW_SDA_Pin;
  GPIO_InitStruct.Mode = GPIO_MODE_OUTPUT_OD;
  GPIO_InitStruct.Pull = GPIO_PULLUP;
  GPIO_InitStruct.Speed = GPIO_SPEED_FREQ_LOW;
  HAL_GPIO_Init(TW_SDA_GPIO_Port, &GPIO_InitStruct);

  /* EXTI interrupt init*/
  HAL_NVIC_SetPriority(EXTI15_10_IRQn, 5, 0);
  HAL_NVIC_EnableIRQ(EXTI15_10_IRQn);

}

/* USER CODE BEGIN 4 */
static void SDRAM_Initialization_Sequence(SDRAM_HandleTypeDef *hsdram, FMC_SDRAM_CommandTypeDef *Command)
{

       __IO uint32_t tmpmrd = 0;

       /* Step 3:  Configure a clock configuration enable command */
       Command->CommandMode = FMC_SDRAM_CMD_CLK_ENABLE;
       Command->CommandTarget = FMC_SDRAM_CMD_TARGET_BANK2;
       Command->AutoRefreshNumber = 1;
       Command->ModeRegisterDefinition = 0;

       /* Send the command */
       HAL_SDRAM_SendCommand(hsdram, Command, 0x1000);

       /* Step 4: Insert 100 ms delay */
       HAL_Delay(100);

       /* Step 5: Configure a PALL (precharge all) command */
       Command->CommandMode = FMC_SDRAM_CMD_PALL;
       Command->CommandTarget = FMC_SDRAM_CMD_TARGET_BANK2;
       Command->AutoRefreshNumber = 1;
       Command->ModeRegisterDefinition = 0;

       /* Send the command */
       HAL_SDRAM_SendCommand(hsdram, Command, 0x1000);

       /* Step 6 : Configure a Auto-Refresh command */
       Command->CommandMode = FMC_SDRAM_CMD_AUTOREFRESH_MODE;
       Command->CommandTarget = FMC_SDRAM_CMD_TARGET_BANK2;
       Command->AutoRefreshNumber = 4;
       Command->ModeRegisterDefinition = 0;

       /* Send the command */
       HAL_SDRAM_SendCommand(hsdram, Command, 0x1000);

       //Step 7: Program the external memory mode register
       // Write burst: single location access
       // Standard operation, CAS latency: 3, Sequential
       // Burst length: 2
       tmpmrd = (uint32_t) 0x00000231;
       Command->CommandMode = FMC_SDRAM_CMD_LOAD_MODE;
       Command->CommandTarget = FMC_SDRAM_CMD_TARGET_BANK2;
       Command->AutoRefreshNumber = 1;
       Command->ModeRegisterDefinition = tmpmrd;

       //Send the command
       HAL_SDRAM_SendCommand(hsdram, Command, 0x1000);

       //Step 8: Set the refresh rate counter
       // SDRAM clock frequency = 100Mhz
       // The refresh operation must be performed 4096 times within 64ms
       // refresh rate = 64ms/4096 = 15.625us
       // COUNT = 15.62us x 100MHz - 20 = 1542
       HAL_SDRAM_ProgramRefreshRate(hsdram, 1542);

}
/* USER CODE END 4 */

void Error_Handler(void)
{
  /* USER CODE BEGIN Error_Handler_Debug */
	printf("err\r\n");
  /* User can add his own implementation to report the HAL error return state */
  __disable_irq();
  while (1)
  {
  }
  /* USER CODE END Error_Handler_Debug */
}
